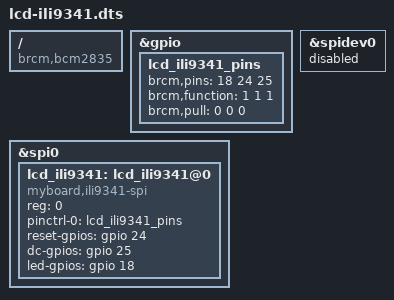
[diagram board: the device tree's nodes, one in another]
/dts-v1/;
/plugin/;

/ {
	compatible = "brcm,bcm2835";

	fragment@0 {
		target = <&gpio>;
		__overlay__ {
			lcd_ili9341_pins: lcd_ili9341_pins {
				brcm,pins = <18 24 25>;  /* led rst dc  */
				brcm,function = <1 1 1>; /* out out out */
				brcm,pull = <0 0 0>;     /* -   -   -   */
			};
		};
	};

	fragment@1 {
		target = <&spidev0>;
		__overlay__ {
			status = "disabled";
		};
	};

	fragment@2 {
		target = <&spi0>;
		__overlay__ {
			/* needed to avoid dtc warning */
			#address-cells = <1>;
			#size-cells = <0>;

			status = "okay";

			lcd_ili9341: lcd_ili9341@0{
				compatible = "myboard,ili9341-spi";
				reg = <0>;
				pinctrl-names = "default";
				pinctrl-0 = <&lcd_ili9341_pins>;

				reset-gpios = <&gpio 24 0>;
				dc-gpios = <&gpio 25 0>;
				led-gpios = <&gpio 18 0>;
			};
		};
	};

};


